AUTOSAR XML (schema 00049)
package /MICROSAR/BswM_swc
  mode declaration group ESH_Mode: category=EXPLICIT_ORDER, initial-mode=STARTUP, on-transition-value=5
    5 x mode:
      STARTUP: value=0
      RUN: value=1
      POSTRUN: value=2
      WAKEUP: value=3
      SHUTDOWN: value=4
  mode declaration group ESH_RunRequest: category=EXPLICIT_ORDER, initial-mode=ESH_RunRequest/RELEASED, on-transition-value=2
    mode RELEASED: value=0
    mode REQUESTED: value=1
  mode declaration group ESH_KillAllRun: category=EXPLICIT_ORDER, initial-mode=ESH_KillAllRun/RELEASED, on-transition-value=2
    mode RELEASED: value=0
    mode REQUESTED: value=1
  data type mapping set BswMMappingSet  # Contains Mapping for ModeDeclarations Groups which are provided by BswM.
    mode-request-type-maps:
      implementation-data-type=BswM_ESH_Mode, mode-group=ESH_Mode
      implementation-data-type=BswM_ESH_RunRequest, mode-group=ESH_RunRequest
      implementation-data-type=BswM_ESH_KillAllRun, mode-group=ESH_KillAllRun
package /MICROSAR/BswM_swc/DataTypes
  impl type BswM_ESH_Mode: compu {0=STARTUP, 1=RUN, 2=POSTRUN, 3=WAKEUP, 4=SHUTDOWN}, range raw 0..255, implementation-data-type=uint8  # Unique value for each user
  impl type BswM_ESH_RunRequest: compu {0=RELEASED, 1=REQUESTED}, range raw 0..255, implementation-data-type=uint8  # Unique value for each user
  impl type BswM_ESH_KillAllRun: compu {0=RELEASED, 1=REQUESTED}, range raw 0..255, implementation-data-type=uint8  # Unique value for each user
package /MICROSAR/BswM_swc/Interfaces
  mode switch interface BswM_MSI_ESH_Mode: is-service=true, service-kind=BASIC-SOFTWARE-MODE-MANAGER
    mode group BswM_MDGP_ESH_Mode: type=ESH_Mode
  sender receiver interface BswM_SRI_BswM_MSI_ESH_Mode_BswM_MDGP_ESH_Mode: is-service=true, service-kind=BASIC-SOFTWARE-MODE-MANAGER
    data requestedMode: type=BswM_ESH_Mode
  mode switch interface BswM_MSI_ESH_RunRequest: is-service=true, service-kind=BASIC-SOFTWARE-MODE-MANAGER
    mode group BswM_MDGP_ESH_RunRequest: type=ESH_RunRequest
  sender receiver interface BswM_SRI_BswM_MSI_ESH_RunRequest_BswM_MDGP_ESH_RunRequest: is-service=true, service-kind=BASIC-SOFTWARE-MODE-MANAGER
    data requestedMode: type=BswM_ESH_RunRequest
  mode switch interface BswM_MSI_ESH_KillAllRun: is-service=true, service-kind=BASIC-SOFTWARE-MODE-MANAGER
    mode group BswM_MDGP_ESH_KillAllRun: type=ESH_KillAllRun
  sender receiver interface BswM_SRI_BswM_MSI_ESH_KillAllRun_BswM_MDGP_ESH_KillAllRun: is-service=true, service-kind=BASIC-SOFTWARE-MODE-MANAGER
    data requestedMode: type=BswM_ESH_KillAllRun
package /MICROSAR/BswM_swc/ComponentTypes
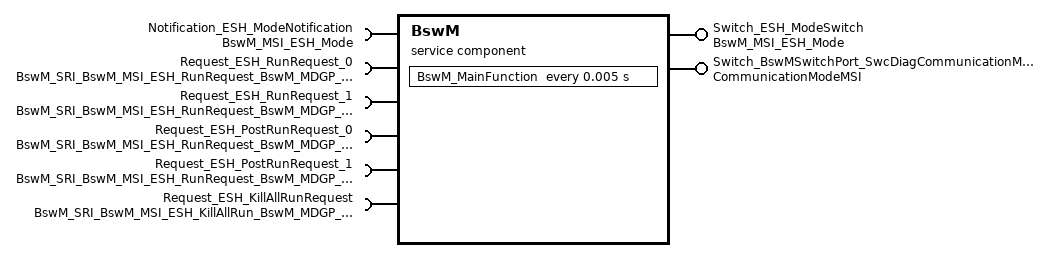
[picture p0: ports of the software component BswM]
  service sw component type BswM: category=SERVICE_COMPONENT
    provide port Switch_ESH_ModeSwitch: provided-interface=BswM_MSI_ESH_Mode
    6 x require port:
      Notification_ESH_ModeNotification: required-interface=BswM_MSI_ESH_Mode
      Request_ESH_RunRequest_0: nonqueued-receiver-com-spec{data-element=BswM_SRI_BswM_MSI_ESH_RunRequest_BswM_MDGP_ESH_RunRequest/requestedMode, handle-out-of-range-status=SILENT, init-value=RELEASED}, required-interface=BswM_SRI_BswM_MSI_ESH_RunRequest_BswM_MDGP_ESH_RunRequest
      Request_ESH_RunRequest_1: nonqueued-receiver-com-spec{data-element=BswM_SRI_BswM_MSI_ESH_RunRequest_BswM_MDGP_ESH_RunRequest/requestedMode, handle-out-of-range-status=SILENT, init-value=RELEASED}, required-interface=BswM_SRI_BswM_MSI_ESH_RunRequest_BswM_MDGP_ESH_RunRequest
      Request_ESH_PostRunRequest_0: nonqueued-receiver-com-spec{data-element=BswM_SRI_BswM_MSI_ESH_RunRequest_BswM_MDGP_ESH_RunRequest/requestedMode, handle-out-of-range-status=SILENT, init-value=RELEASED}, required-interface=BswM_SRI_BswM_MSI_ESH_RunRequest_BswM_MDGP_ESH_RunRequest
      Request_ESH_PostRunRequest_1: nonqueued-receiver-com-spec{data-element=BswM_SRI_BswM_MSI_ESH_RunRequest_BswM_MDGP_ESH_RunRequest/requestedMode, handle-out-of-range-status=SILENT, init-value=RELEASED}, required-interface=BswM_SRI_BswM_MSI_ESH_RunRequest_BswM_MDGP_ESH_RunRequest
      Request_ESH_KillAllRunRequest: nonqueued-receiver-com-spec{data-element=BswM_SRI_BswM_MSI_ESH_KillAllRun_BswM_MDGP_ESH_KillAllRun/requestedMode, handle-out-of-range-status=SILENT, init-value=RELEASED}, required-interface=BswM_SRI_BswM_MSI_ESH_KillAllRun_BswM_MDGP_ESH_KillAllRun
    provide port Switch_BswMSwitchPort_SwcDiagCommunicationMode: provided-interface=CommunicationModeMSI
    behavior BswMInternalBehavior: data-type-mapping=BswMMappingSet, handle-termination-and-restart=NO-SUPPORT, included-data-type-set=data-type=[BswM_ESH_Mode, BswM_ESH_RunRequest, BswM_ESH_KillAllRun]
      timing event Timer_BswM_MainFunction: start-on-event=BswM_MainFunction, period=0.005
      port-api-options:
        enable-take-address=true, indirect-api=false, port=Switch_ESH_ModeSwitch
        enable-take-address=true, indirect-api=false, port=Notification_ESH_ModeNotification
        enable-take-address=true, indirect-api=false, port=Request_ESH_RunRequest_0
        enable-take-address=true, indirect-api=false, port=Request_ESH_RunRequest_1
        enable-take-address=true, indirect-api=false, port=Request_ESH_PostRunRequest_0
        enable-take-address=true, indirect-api=false, port=Request_ESH_PostRunRequest_1
        enable-take-address=true, indirect-api=false, port=Request_ESH_KillAllRunRequest
        enable-take-address=true, indirect-api=false, port=Switch_BswMSwitchPort_SwcDiagCommunicationMode
      runnable BswM_MainFunction: mode-access-point=Notification_ESH_ModeNotification.BswM_MDGP_ESH_Mode
        data-receive-point-by-arguments:
          5 x access:
            DataReceivePointBswM_MainFunction_Request_ESH_RunRequest_0_requestedMode: accessed-variable=Request_ESH_RunRequest_0.requestedMode
            DataReceivePointBswM_MainFunction_Request_ESH_RunRequest_1_requestedMode: accessed-variable=Request_ESH_RunRequest_1.requestedMode
            DataReceivePointBswM_MainFunction_Request_ESH_PostRunRequest_0_requestedMode: accessed-variable=Request_ESH_PostRunRequest_0.requestedMode
            DataReceivePointBswM_MainFunction_Request_ESH_PostRunRequest_1_requestedMode: accessed-variable=Request_ESH_PostRunRequest_1.requestedMode
            DataReceivePointBswM_MainFunction_Request_ESH_KillAllRunRequest_requestedMode: accessed-variable=Request_ESH_KillAllRunRequest.requestedMode
        mode switch point ModeSwitchPointBswM_MainFunction_Switch_ESH_ModeSwitch_BswM_MDGP_ESH_Mode: mode-group=Switch_ESH_ModeSwitch.BswM_MDGP_ESH_Mode
        mode switch point ModeSwitchPointBswM_MainFunction_Switch_BswMSwitchPort_SwcDiagCommunicationMode_Mode: mode-group=Switch_BswMSwitchPort_SwcDiagCommunicationMode.Mode
  swc implementation BswMImplementation: programming-language=C, behavior=BswMInternalBehavior
    resource consumption BswMResourceConsumption
      5 x memory section:
        BswM_START_SEC_CODE: sw-addrmethod=CODE, symbol=CODE
        BswM_START_SEC_CONST_UNSPECIFIED: alignment=UNSPECIFIED, sw-addrmethod=CONST, symbol=CONST_UNSPECIFIED
        BswM_START_SEC_VAR_NOINIT_UNSPECIFIED: alignment=UNSPECIFIED, sw-addrmethod=VAR_NO_INIT, symbol=VAR_NOINIT_UNSPECIFIED
        BswM_START_SEC_VAR_INIT_UNSPECIFIED: alignment=UNSPECIFIED, sw-addrmethod=VAR_INIT, symbol=VAR_INIT_UNSPECIFIED
        BswM_START_SEC_VAR_ZERO_INIT_UNSPECIFIED: alignment=UNSPECIFIED, sw-addrmethod=VAR_CLEARED, symbol=VAR_ZERO_INIT_UNSPECIFIED
